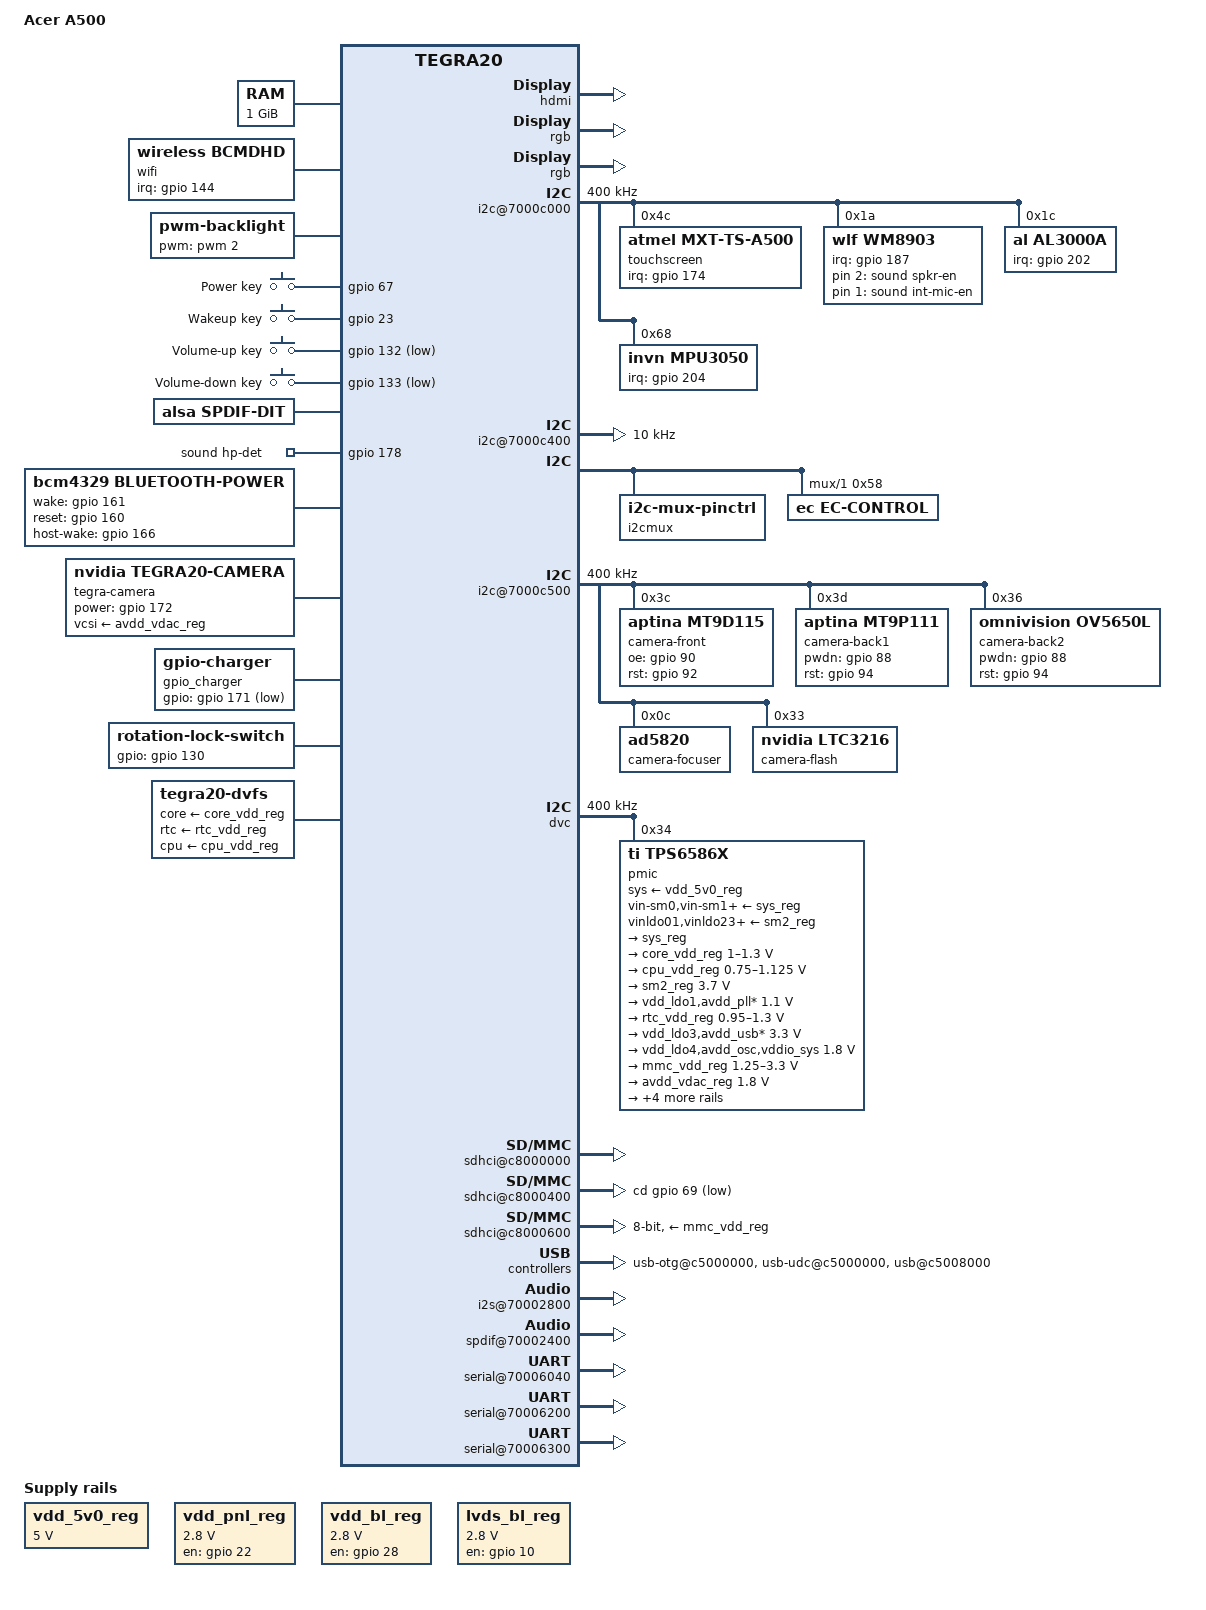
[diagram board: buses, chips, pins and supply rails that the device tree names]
/dts-v1/;

/*
 * Carveouts for multimedia and ram console
 * 256MB - multimedia
 * 9MB - fb1
 * 16MB - fb2
 * 1MB - console
 */
/memreserve/ 0x2E600000 0x11A00000;

/include/ "tegra20.dtsi"

/ {
	model = "Acer A500";
	compatible = "acer,picasso", "nvidia,tegra20";

	memory {
		reg = <0x00000000 0x40000000>;
	};

	nvmap {
		compatible = "nvidia,tegra-nvmap";
		#address-cells = <1>;
		#size-cells = <1>;
		ranges;

		carveouts {
			#address-cells = <1>;
			#size-cells = <1>;
			ranges;

			iram {
				reg = <0x40000400 0x3FC00>;
				reg-names = "iram";
				buddy-size = <0>;
				usage-mask = <0x20000000>;
			};

			generic {
				reg = <0x2E600000 0x10000000>;
				reg-names = "generic-0";
				buddy-size = <0x8000>;
				usage-mask = <0x1>;
			};
		};
	};

	host1x {
		compatible = "nvidia,tegra20-host1x", "nvhost-bus";
		ranges;

		hdmi {
			status = "okay";

			vdd-supply = <&hdmi_vdd_reg>;
			pll-supply = <&hdmi_pll_reg>;

			nvidia,ddc-i2c-bus = <&hdmi_ddc>;
			nvidia,hpd-gpio = <&gpio 111 0>; /* PN7 */
		};

		dc@54200000 {
			reg = <0x54200000 0x00040000>,
			      <0x3E600000 0x00900000>;
			reg-names = "regs", "fbmem";
			interrupt-names = "irq";

			lvds-vdd-supply = <&lvds_bl_reg>;
			pnl-vdd-supply = <&vdd_pnl_reg>;
			bl-vdd-supply = <&vdd_bl_reg>;

			rgb {
				status = "okay";

				display {
					fb-win = <0>;
					fb-xres = <1280>;
					fb-yres = <800>;
					fb-bpp = <32>;

					lvds-to-bl = <330>;

					dc-index = <0>;

					flags = <1>; /* TEGRA_DC_FLAG_ENABLED */

					type = <0>; /* TEGRA_DC_OUT_RGB */
					order = <0>; /* TEGRA_DC_ORDER_RED_BLUE */
					align = <0>; /* TEGRA_DC_ALIGN_MSB */
					depth = <18>;
					dither = <2>; /* TEGRA_DC_ORDERED_DITHER */

					default-emc-rate = <600000000>;
					min-emc-rate = <300000000>;

					display-timings {
						native-mode = <&timing0>;
						timing0: 1280x800 {
							clock-frequency = <70500000>;
							hactive = <1280>;
							vactive = <800>;
							hfront-porch = <58>;
							hback-porch = <4>;
							hsync-len = <58>;
							vsync-len = <4>;
							vfront-porch = <58>;
							vback-porch = <4>;
						};
					};
				};
			};
		};

		dc@54240000 {
			reg = <0x54240000 0x00040000>,
			      <0x54280000 0x00040000>,
			      <0x3EF00000 0x01000000>;
			reg-names = "regs", "hdmi_regs", "fbmem";
			interrupt-names = "irq";

			hdmi-vdd-supply = <&hdmi_vdd_reg>;
			hdmi-pll-supply = <&hdmi_pll_reg>;

			rgb {
				status = "okay";

				display {
					fb-win = <0>;
					fb-xres = <1280>;
					fb-yres = <800>;
					fb-bpp = <32>;

					dc-index = <1>;

					type = <1>; /* TEGRA_DC_OUT_HDMI */
					order = <0>; /* TEGRA_DC_ORDER_RED_BLUE */
					align = <0>; /* TEGRA_DC_ALIGN_MSB */
					dc-flags = <0>; /* TEGRA_DC_OUT_HOTPLUG_HIGH */
					max-clock = <148500>;
				};
			};
		};
	};

	pinmux {
		pinctrl-names = "default";
		pinctrl-0 = <&state_default>;

		state_default: pinmux {
			ata {
				nvidia,pins = "ata";
				nvidia,function = "ide";
			};
			atb {
				nvidia,pins = "atb", "gma", "gme";
				nvidia,function = "sdio4";
			};
			atc {
				nvidia,pins = "atc";
				nvidia,function = "nand";
			};
			atd {
				nvidia,pins = "atd", "ate", "gmb", "spia",
					"spib", "spic";
				nvidia,function = "gmi";
			};
			cdev1 {
				nvidia,pins = "cdev1";
				nvidia,function = "plla_out";
			};
			cdev2 {
				nvidia,pins = "cdev2";
				nvidia,function = "pllp_out4";
			};
			crtp {
				nvidia,pins = "crtp", "lm1";
				nvidia,function = "crt";
			};
			csus {
				nvidia,pins = "csus";
				nvidia,function = "vi_sensor_clk";
			};
			dap1 {
				nvidia,pins = "dap1";
				nvidia,function = "dap1";
			};
			dap2 {
				nvidia,pins = "dap2";
				nvidia,function = "dap2";
			};
			dap3 {
				nvidia,pins = "dap3";
				nvidia,function = "dap3";
			};
			dap4 {
				nvidia,pins = "dap4";
				nvidia,function = "dap4";
			};
			dta {
				nvidia,pins = "dta", "dtb", "dtc", "dtd", "dte";
				nvidia,function = "vi";
			};
			dtf {
				nvidia,pins = "dtf";
				nvidia,function = "i2c3";
			};
			gmc {
				nvidia,pins = "gmc";
				nvidia,function = "uartd";
			};
			gmd {
				nvidia,pins = "gmd";
				nvidia,function = "sflash";
			};
			gpu {
				nvidia,pins = "gpu";
				nvidia,function = "pwm";
			};
			gpu7 {
				nvidia,pins = "gpu7";
				nvidia,function = "rtck";
			};
			gpv {
				nvidia,pins = "gpv", "slxa";
				nvidia,function = "pcie";
			};
			hdint {
				nvidia,pins = "hdint";
				nvidia,function = "hdmi";
			};
			i2cp {
				nvidia,pins = "i2cp";
				nvidia,function = "i2cp";
			};
			irrx {
				nvidia,pins = "irrx", "irtx";
				nvidia,function = "uartb";
			};
			kbca {
				nvidia,pins = "kbca", "kbcb", "kbcc", "kbcd",
					"kbce", "kbcf";
				nvidia,function = "kbc";
			};
			lcsn {
				nvidia,pins = "lcsn", "ldc", "lm0", "lpw1",
					"lsdi", "lvp0";
				nvidia,function = "rsvd4";
			};
			ld0 {
				nvidia,pins = "ld0", "ld1", "ld2", "ld3", "ld4",
					"ld5", "ld6", "ld7", "ld8", "ld9",
					"ld10", "ld11", "ld12", "ld13", "ld14",
					"ld15", "ld16", "ld17", "ldi", "lhp0",
					"lhp1", "lhp2", "lhs", "lpp", "lsc0",
					"lsc1", "lsck", "lsda", "lspi", "lvp1",
					"lvs";
				nvidia,function = "displaya";
			};
			owc {
				nvidia,pins = "owc", "spdi", "spdo", "uac";
				nvidia,function = "rsvd2";
			};
			pmc {
				nvidia,pins = "pmc";
				nvidia,function = "pwr_on";
			};
			rm {
				nvidia,pins = "rm";
				nvidia,function = "i2c1";
			};
			sdb {
				nvidia,pins = "sdb", "sdc", "sdd", "slxc", "slxk";
				nvidia,function = "sdio3";
			};
			sdio1 {
				nvidia,pins = "sdio1";
				nvidia,function = "sdio1";
			};
			slxd {
				nvidia,pins = "slxd";
				nvidia,function = "spdif";
			};
			spid {
				nvidia,pins = "spid", "spie", "spif";
				nvidia,function = "spi1";
			};
			spig {
				nvidia,pins = "spig", "spih";
				nvidia,function = "spi2_alt";
			};
			uaa {
				nvidia,pins = "uaa", "uab", "uda";
				nvidia,function = "ulpi";
			};
			uad {
				nvidia,pins = "uad";
				nvidia,function = "irda";
			};
			uca {
				nvidia,pins = "uca", "ucb";
				nvidia,function = "uartc";
			};
			conf_ata {
				nvidia,pins = "ata", "atb", "atc", "atd",
					"cdev1", "cdev2", "csus", "dap1",
					"dap4", "dte", "dtf", "gma", "gmc",
					"gme", "gpu", "gpu7", "gpv", "i2cp",
					"irrx", "irtx", "pta", "rm",
					"sdc", "sdd", "slxc", "slxd", "slxk",
					"spdi", "spdo", "uac", "uad", "uda";
				nvidia,pull = <0>;
				nvidia,tristate = <0>;
			};
			conf_ate {
				nvidia,pins = "ate", "dap2", "dap3",
					"gmd", "owc", "spia", "spib", "spic",
					"spid", "spie";
				nvidia,pull = <0>;
				nvidia,tristate = <1>;
			};
			conf_ck32 {
				nvidia,pins = "ck32", "ddrc", "pmca", "pmcb",
					"pmcc", "pmcd", "pmce", "xm2c", "xm2d";
				nvidia,pull = <0>;
			};
			conf_crtp {
				nvidia,pins = "crtp", "gmb", "slxa", "spig",
					"spih";
				nvidia,pull = <2>;
				nvidia,tristate = <1>;
			};
			conf_dta {
				nvidia,pins = "dta", "dtb", "dtc", "dtd", "kbcb";
				nvidia,pull = <1>;
				nvidia,tristate = <0>;
			};
			conf_dte {
				nvidia,pins = "spif";
				nvidia,pull = <1>;
				nvidia,tristate = <1>;
			};
			conf_hdint {
				nvidia,pins = "hdint", "lcsn", "ldc", "lm1",
					"lpw1", "lsck", "lsda", "lsdi",
					"lvp0";
				nvidia,tristate = <1>;
			};
			conf_kbca {
				nvidia,pins = "kbca", "kbcc", "kbcd",
					"kbce", "kbcf", "sdio1", "uaa",
					"uab", "uca", "ucb";
				nvidia,pull = <2>;
				nvidia,tristate = <0>;
			};
			conf_lc {
				nvidia,pins = "lc", "ls";
				nvidia,pull = <2>;
			};
			conf_ld0 {
				nvidia,pins = "ld0", "ld1", "ld2", "ld3", "ld4",
					"ld5", "ld6", "ld7", "ld8", "ld9",
					"ld10", "ld11", "ld12", "ld13", "ld14",
					"ld15", "ld16", "ld17", "ldi", "lhp0",
					"lhp1", "lhp2", "lhs", "lm0", "lpp",
					"lpw0", "lpw2", "lsc0", "lsc1", "lspi",
					"lvp1", "lvs", "pmc", "sdb";
				nvidia,tristate = <0>;
			};
			conf_ld17_0 {
				nvidia,pins = "ld17_0", "ld19_18", "ld21_20",
					"ld23_22";
				nvidia,pull = <1>;
			};
			drive_ddc {
				nvidia,pins = "drive_ddc";
				nvidia,schmitt = <1>;
				nvidia,low-power-mode = <1>;
			};
			drive_vi1 {
				nvidia,pins = "drive_vi1";
				nvidia,schmitt = <1>;
				nvidia,low-power-mode = <1>;
			};
			drive_sdio1 {
				nvidia,pins = "drive_sdio1";
				nvidia,schmitt = <1>;
				nvidia,low-power-mode = <1>;
			};
			drive_dbg {
				nvidia,pins = "drive_dbg";
				nvidia,schmitt = <1>;
				nvidia,low-power-mode = <1>;
				nvidia,slew-rate-rising = <0>;
				nvidia,slew-rate-falling = <0>;
			};
			drive_vi2 {
				nvidia,pins = "drive_vi2";
				nvidia,schmitt = <1>;
				nvidia,low-power-mode = <1>;
				nvidia,slew-rate-rising = <0>;
				nvidia,slew-rate-falling = <0>;
			};
			drive_at1 {
				nvidia,pins = "drive_at1";
				nvidia,schmitt = <1>;
				nvidia,low-power-mode = <1>;
				nvidia,slew-rate-rising = <0>;
				nvidia,slew-rate-falling = <0>;
			};
			drive_ao1 {
				nvidia,pins = "drive_ao1";
				nvidia,schmitt = <1>;
				nvidia,low-power-mode = <1>;
				nvidia,slew-rate-rising = <0>;
				nvidia,slew-rate-falling = <0>;
			};
		};

		state_i2cmux_ddc: pinmux_i2cmux_ddc {
			ddc {
				nvidia,pins = "ddc";
				nvidia,function = "i2c2";
			};
			pta {
				nvidia,pins = "pta";
				nvidia,function = "rsvd4";
			};
		};

		state_i2cmux_pta: pinmux_i2cmux_pta {
			ddc {
				nvidia,pins = "ddc";
				nvidia,function = "rsvd4";
			};
			pta {
				nvidia,pins = "pta";
				nvidia,function = "i2c2";
			};
		};

		state_i2cmux_idle: pinmux_i2cmux_idle {
			ddc {
				nvidia,pins = "ddc";
				nvidia,function = "rsvd4";
			};
			pta {
				nvidia,pins = "pta";
				nvidia,function = "rsvd4";
			};
		};
	};

	i2c@7000c000 {
		status = "okay";
		clock-frequency = <400000>;

		touchscreen@4c {
			compatible = "atmel,mxt-ts-a500";
			reg = <0x4c>;
			interrupt-parent = <&gpio>;
			interrupts = <174 0x2>;

			android-evdev;
			multislot-proto;

			x-size = <1280>;
			y-size = <800>;

			config = /bits/ 8 <
				/* MXT_GEN_COMMAND(6) */
				0x00 0x00 0x00 0x00 0x00 0x00
				/* MXT_GEN_POWER(7) */
				0x32 0x0a 0x32
				/* MXT_GEN_ACQUIRE(8) */
				0x0a 0x00 0x0a 0x0a 0x00 0x00 0x05
				0x0a 0x1e 0x19
				/* MXT_TOUCH_MULTI(9) */
				0x8f 0x00 0x00 0x1c 0x29 0x00 0x10
				0x37 0x03 0x01 0x00 0x05 0x05 0x20
				0x0a 0x05 0x0a 0x05 0x1f 0x03 0xff
				0x04 0x00 0x00 0x00 0x00 0x98 0x22
				0xd4 0x16 0x0a 0x0a 0x00 0x00
				/* MXT_TOUCH_KEYARRAY(15-1) */
				0x01 0x18 0x29 0x04 0x01 0x00 0x00
				0xff 0x01 0x00 0x00
				/* MXT_TOUCH_KEYARRAY(15-2) */
				0x00 0x00 0x00 0x00 0x00 0x00 0x00
				0x00 0x00 0x00 0x00
				/* MXT_SPT_COMMSCONFIG(18) */
				0x00 0x00
				/* MXT_PROCG_NOISE(22) */
				0x05 0x00 0x00 0x00 0x00 0x00 0x00
				0x00 0x2D 0x00 0x00 0x0b 0x11 0x16
				0x20 0x24 0x00
				/* MXT_PROCI_ONETOUCH(24) */
				0x00 0x00 0x00 0x00 0x00 0x00 0x00
				0x00 0x00 0x00 0x00 0x00 0x00 0x00
				0x00 0x00 0x00 0x00 0x00
				/* MXT_SPT_SELFTEST(25) */
				0x00 0x00 0x00 0x00 0x00 0x00 0x00
				0x00 0x00 0x00 0x00 0x00 0x00 0x00
				/* MXT_PROCI_TWOTOUCH(27) */
				0x00 0x00 0x00 0x00 0x00 0x00 0x00
				/* MXT_SPT_CTECONFIG(28) */
				0x00 0x00 0x00 0x10 0x10 0x3c
				/* MXT_PROCI_GRIP(40) */
				0x00 0x00 0x00 0x00 0x00
				/* MXT_PROCI_PALM(41) */
				0x00 0x00 0x00 0x00 0x00 0x00
				/* MXT_TOUCH_PROXIMITY(43) */
				0x00 0x00 0x00 0x00 0x00 0x00>;
		};

		wm8903: wm8903@1a {
			compatible = "wlf,wm8903";
			reg = <0x1a>;
			interrupt-parent = <&gpio>;
			interrupts = <187 0x04>;

			gpio-controller;
			#gpio-cells = <2>;

			micdet-cfg = <0>;
			micdet-delay = <500>;
			gpio-cfg = <0 0 0 0xffffffff 0xffffffff>;
		};

		al3000a@1c {
			compatible = "al,al3000a";
			reg = <0x1c>;
			interrupt-parent = <&gpio>;
			interrupts = <202 0x04>; /* GPIO PZ2 */
		};

		mpu3050@68 {
			compatible = "invn,mpu3050";
			reg = <0x68>;
			interrupt-parent = <&gpio>;
			interrupts = <204 0x04>; /* gpio PZ4 */

			compass-i2c-bus = <&dvc>;
			compass-yamaha-i2c-bus = <&dvc>;

			int-config = <0x10>;
			level-shifter = <0>;
			orientation = /bits/ 8 <0	0xff	0
						0xff	0	0
						0	0	0xff>;

			accelerometer {
				interrupt-parent = <&gpio>;
				interrupts = <151 0x04>; /* gpio PS7 */

				bus-secondary;
				address = <0xf>;
				orientation = /bits/ 8 <0	0xff	0
							0xff	0	0
							0	0	0xff>;
			};

			compass {
				interrupt-parent = <&gpio>;
				interrupts = <109 0x04>; /* gpio PN5 */

				bus-primary;
				address = <0xc>;
				orientation = /bits/ 8 <1	0	0
							0	0xff	0
							0	0	0xff>;
			};
		};
	};

	i2c@7000c400 {
		status = "okay";
		clock-frequency = <10000>;
	};

	i2cmux {
		compatible = "i2c-mux-pinctrl";
		#address-cells = <1>;
		#size-cells = <0>;

		i2c-parent = <&{/i2c@7000c400}>;

		pinctrl-names = "ddc", "pta", "idle";
		pinctrl-0 = <&state_i2cmux_ddc>;
		pinctrl-1 = <&state_i2cmux_pta>;
		pinctrl-2 = <&state_i2cmux_idle>;

		hdmi_ddc: i2c@0 {
			reg = <0>;
			#address-cells = <1>;
			#size-cells = <0>;
		};

		i2c@1 {
			reg = <1>;
			#address-cells = <1>;
			#size-cells = <0>;

			ec-control@58 {
				compatible = "ec,ec-control";
				reg = <0x58>;
				ec,i2c-retry-count = <5>;
				ec,lsc-start-delay = <25000>;
				system-power-controller;
				leds-reset;

				battery {
					compatible = "ec,ec-battery";
					power-supply = <&gpio_charger>;
				};

				leds {
					compatible = "ec,ec-leds";
				};
			};
		};
	};

	i2c@7000c500 {
		status = "okay";
		clock-frequency = <400000>;

		camera-front@3c {
			compatible = "aptina,mt9d115";
			reg = <0x3c>;
			oe-gpio = <&gpio 90 0>; /* gpio PL2 */
			rst-gpio = <&gpio 92 0>; /* gpio PL4 */
		};

		camera-back1@3d {
			compatible = "aptina,mt9p111";
			reg = <0x3d>;
			pwdn-gpio = <&gpio 88 0>; /* gpio PL0 */
			rst-gpio = <&gpio 94 0>; /* gpio PL6 */
		};

		camera-back2@36 {
			compatible = "omnivision,ov5650l";
			reg = <0x36>;
			pwdn-gpio = <&gpio 88 0>; /* gpio PL0 */
			rst-gpio = <&gpio 94 0>; /* gpio PL6 */
		};

		camera-focuser@0c {
			compatible = "ad5820";
			reg = <0x0c>;
		};

		camera-flash@33 {
			compatible = "nvidia,ltc3216";
			reg = <0x33>;
		};
	};

	regulators {
		compatible = "simple-bus";
		#address-cells = <1>;
		#size-cells = <0>;

		vdd_5v0_reg: regulator@0 {
			compatible = "regulator-fixed";
			reg = <0>;
			regulator-name = "vdd_5v0";
			regulator-min-microvolt = <5000000>;
			regulator-max-microvolt = <5000000>;
			regulator-always-on;
		};

		vdd_pnl_reg: regulator@1 {
			compatible = "regulator-fixed";
			reg = <1>;
			regulator-name = "vdd_pnl";
			regulator-min-microvolt = <2800000>;
			regulator-max-microvolt = <2800000>;
			gpio = <&gpio 22 0>; /* gpio PC6 */
			enable-active-high;
			regulator-boot-on;
		};

		vdd_bl_reg: regulator@2 {
			compatible = "regulator-fixed";
			reg = <2>;
			regulator-name = "vdd_bl";
			regulator-min-microvolt = <2800000>;
			regulator-max-microvolt = <2800000>;
			gpio = <&gpio 28 0>; /* gpio PD4 */
			enable-active-high;
			regulator-boot-on;
		};

		lvds_bl_reg: regulator@3 {
			compatible = "regulator-fixed";
			reg = <3>;
			regulator-name = "vdd_lvds";
			regulator-min-microvolt = <2800000>;
			regulator-max-microvolt = <2800000>;
			gpio = <&gpio 10 0>; /* gpio PB2 */
			enable-active-high;
			regulator-boot-on;
		};
	};

	dvc: i2c@7000d000 {
		status = "okay";
		clock-frequency = <400000>;

		pmic: tps6586x@34 {
			compatible = "ti,tps6586x";
			reg = <0x34>;
			interrupts = <0 86 0>;

			#gpio-cells = <2>;
			gpio-controller;

			sys-supply = <&vdd_5v0_reg>;
			vin-sm0-supply = <&sys_reg>;
			vin-sm1-supply = <&sys_reg>;
			vin-sm2-supply = <&sys_reg>;
			vinldo01-supply = <&sm2_reg>;
			vinldo23-supply = <&sm2_reg>;
			vinldo4-supply = <&sm2_reg>;
			vinldo678-supply = <&sm2_reg>;
			vinldo9-supply = <&sm2_reg>;

			regulators {
				sys_reg: sys {
					regulator-name = "vdd_sys";
					regulator-always-on;
				};

				core_vdd_reg: sm0 {
					regulator-name = "vdd_sm0,vdd_core";
					regulator-min-microvolt = <1000000>;
					regulator-max-microvolt = <1300000>;
					regulator-always-on;
				};

				cpu_vdd_reg: sm1 {
					regulator-name = "vdd_sm1,vdd_cpu";
					regulator-min-microvolt = <750000>;
					regulator-max-microvolt = <1125000>;
					regulator-always-on;
				};

				sm2_reg: sm2 {
					regulator-name = "vdd_sm2,vin_ldo*";
					regulator-min-microvolt = <3700000>;
					regulator-max-microvolt = <3700000>;
					regulator-always-on;
				};

				/* LDO0 is not connected to anything */

				ldo1 {
					regulator-name = "vdd_ldo1,avdd_pll*";
					regulator-min-microvolt = <1100000>;
					regulator-max-microvolt = <1100000>;
					regulator-always-on;
				};

				rtc_vdd_reg: ldo2 {
					regulator-name = "vdd_ldo2,vdd_rtc";
					regulator-min-microvolt = <950000>;
					regulator-max-microvolt = <1300000>;
				};

				ldo3 {
					regulator-name = "vdd_ldo3,avdd_usb*";
					regulator-min-microvolt = <3300000>;
					regulator-max-microvolt = <3300000>;
					regulator-always-on;
				};

				ldo4 {
					regulator-name = "vdd_ldo4,avdd_osc,vddio_sys";
					regulator-min-microvolt = <1800000>;
					regulator-max-microvolt = <1800000>;
					regulator-always-on;
				};

				mmc_vdd_reg: ldo5 {
					regulator-name = "vdd_ldo5,vcore_mmc";
					regulator-min-microvolt = <1250000>;
					regulator-max-microvolt = <3300000>;
					regulator-always-on;
				};

				avdd_vdac_reg: ldo6 {
					regulator-name = "vdd_ldo6,avdd_vdac";
					regulator-min-microvolt = <1800000>;
					regulator-max-microvolt = <1800000>;
				};

				hdmi_vdd_reg: ldo7 {
					regulator-name = "vdd_ldo7,avdd_hdmi";
					regulator-min-microvolt = <3300000>;
					regulator-max-microvolt = <3300000>;
				};

				hdmi_pll_reg: ldo8 {
					regulator-name = "vdd_ldo8,avdd_hdmi_pll";
					regulator-min-microvolt = <1800000>;
					regulator-max-microvolt = <1800000>;
				};

				ldo9 {
					regulator-name = "vdd_ldo9,avdd_2v85,vdd_ddr_rx";
					regulator-min-microvolt = <2850000>;
					regulator-max-microvolt = <2850000>;
				};

				ldo_rtc {
					regulator-name = "vdd_rtc_out,vdd_cell";
					regulator-min-microvolt = <3300000>;
					regulator-max-microvolt = <3300000>;
				};
			};
		};
	};

	pmc {
		nvidia,invert-interrupt;
	};

	sdhci@c8000000 {
		status = "okay";
	};

	sdhci@c8000400 {
		status = "okay";
		cd-gpios = <&gpio 69 1>; /* gpio PI5 */
		power-gpios = <&gpio 70 0>; /* gpio PI6 */
	};

	sdhci@c8000600 {
		status = "okay";
		built-in;
		bus-width = <8>;
		vmmc-supply = <&mmc_vdd_reg>;
	};

	wifi {
		compatible = "wireless,bcmdhd";
		interrupt-parent = <&gpio>;
		interrupts = <144 0x04>; /* gpio PS0 */
		interrupt-names = "bcmdhd_wlan_irq";
	};

	usb-otg@c5000000 {
		compatible = "nvidia,tegra20-otg";
		reg = <0xc5000000 0x4000>;
		interrupts = <0 20 0x04>;
		nvidia,vbus-gpio = <&gpio 24 0>; /* gpio PD0 */
	};

	usb-udc@c5000000 {
		compatible = "nvidia,tegra20-udc";
		reg = <0xc5000000 0x4000>;
		interrupts = <0 20 0x04>;
	};

	usb@c5008000 {
		status = "okay";
		nvidia,vbus-gpio = <&gpio 27 0>; /* gpio PD3 */
	};

	ram-console {
		compatible = "android,ram-console";
		reg = <0x3FF00000 0x00100000>;
	};

	backlight {
		compatible = "pwm-backlight";
		pwms = <&pwm 2 41667>;

		brightness-levels = <0 1 2 3 4 5 6 7 8 9 10 11 12 13 14 15 16 17
				18 19 20 21 22 23 24 25 26 27 28 29 30 31 32 33
				34 35 36 37 38 39 40 41 42 43 44 45 46 47 48 49
				50 51 52 53 54 55 56 57 58 59 60 61 62 63 64 65
				66 67 68 69 70 71 72 73 74 75 76 77 78 79 80 81
				82 83 84 85 86 87 88 89 90 91 92 93 94 95 96 97
				98 99 100 101 102 103 104 105 106 107 108 109
				110 111 112 113 114 115 116 117 118 119 120 121
				122 123 124 125 126 127 128 129 130 131 132 133
				134 135 136 137 138 139 140 141 142 143 144 145
				146 147 148 149 150 151 152 153 154 155 156 157
				158 159 160 161 162 163 164 165 166 167 168 169
				170 171 172 173 174 175 176 177 178 179 180 181
				182 183 184 185 186 187 188 189 190 191 192 193
				194 195 196 197 198 199 200 201 202 203 204 205
				206 207 208 209 210 211 212 213 214 215 216 217
				218 219 220 221 222 223 224 225 226 227 228 229
				230 231 232 233 234 235 236 237 238 239 240 241
				242 243 244 245 246 247 248 249 250 251 252 253
				254 255>;

		default-brightness-level = <224>;
	};

	gpio-keys {
		compatible = "gpio-keys";

		power {
			label = "Power key";
			gpios = <&gpio 67 0>; /* gpio PI3 */
			linux,code = <116>; /* KEY_POWER */
			debounce-interval = <0>;
		};

		wakeup {
			label = "Wakeup key";
			gpios = <&gpio 23 0>; /* gpio PC7 */
			linux,code = <116>; /* KEY_POWER */
			gpio-key,wakeup;
			debounce-interval = <0>;
		};

		volume-up {
			label = "Volume-up key";
			gpios = <&gpio 132 1>; /* gpio PQ4 */
			linux,code = <115>; /* KEY_VOLUMEUP */
			debounce-interval = <10>;
		};

		volume-down {
			label = "Volume-down key";
			gpios = <&gpio 133 1>; /* gpio PQ5 */
			linux,code = <114>; /* KEY_VOLUMEDOWN */
			debounce-interval = <10>;
		};
	};

	i2s@70002800 {
		status = "okay";
	};

	spdif-dit {
		compatible = "alsa,spdif-dit";
	};

	spdif@70002400 {
		compatible = "nvidia,tegra20-spdif";
		reg = <0x70002400 0x00000200>,
		      <0x00000003 0x00000003>;
		reg-names = "regs", "dma";
	};

	sound {
		compatible = "nvidia,tegra-audio-wm8903-picasso",
			     "nvidia,tegra-audio-wm8903";
		nvidia,model = "WM8903 NVIDIA Tegra Picasso";

		nvidia,audio-routing =
			"Headphone Jack", "HPOUTR",
			"Headphone Jack", "HPOUTL",
			"Int Spk", "LINEOUTL",
			"Int Spk", "LINEOUTR",
			"Mic Jack", "MICBIAS",
			"IN2L", "Mic Jack",
			"IN2R", "Mic Jack",
			"Int Mic", "MICBIAS",
			"IN1L", "Int Mic",
			"IN1R", "Int Mic";

		nvidia,i2s-controller = <&tegra_i2s1>;
		nvidia,audio-codec = <&wm8903>;

		nvidia,spkr-en-gpios = <&wm8903 2 0>;
		nvidia,hp-det-gpios = <&gpio 178 0>; /* gpio PW2 */
		nvidia,int-mic-en-gpios = <&wm8903 1 0>; /* gpio FM2018 */

		vdd_dmic-supply = <&avdd_vdac_reg>;
	};

	serial@70006040 {
		status = "okay";
		compatible = "nvidia,tegra20-hsuart";
		nvidia,dma-request-selector = <&apbdma 9>;
	};

	serial@70006200 {
		status = "okay";
		compatible = "nvidia,tegra20-hsuart";
		nvidia,dma-request-selector = <&apbdma 10>;
	};

	serial@70006300 {
		status = "okay";
		compatible = "nvidia,tegra20-hsuart";
		nvidia,dma-request-selector = <&apbdma 19>;
	};

	bluetooth-power {
		compatible = "bcm4329,bluetooth-power";

		wake-gpio = <&gpio 161 0>; /* gpio PU1 */
		reset-gpio = <&gpio 160 0>; /* gpio PU0 */
		host-wake-gpio = <&gpio 166 0>; /* gpio PU6 */
	};

	tegra-avp {
		compatible = "nvidia,tegra20-avp";
		interrupts = <0 4 0x04>;
		interrupt-names = "mbox_from_avp_pending";
	};

	tegra-camera {
		compatible = "nvidia,tegra20-camera";
		power-gpio = <&gpio 172 0>; /* gpio PV4 */
		vcsi-supply = <&avdd_vdac_reg>;
	};

	tegra-aes@6001a000 {
		compatible = "nvidia,tegra20-aes";
		reg = <0x6001a000 0x3c00>;
		interrupts = <0 10 0x04>;
	};

	timed-gpio {
		compatible = "android,timed-gpio";

		vibrator {
			gpio = <&gpio 173 0>; /* gpio PV5 */
			name = "vibrator";
			max-timeout = <10000>;
		};
	};

	wakeups {
		compatible = "nvidia,tegra20-wakeups";

		gpio-events-1 {
			interrupt-parent = <&gpio>;
			interrupts = <117 0>, /* PO5 */
				     <171 0>, /* PV3 */
				     <89  0>, /* PL1 */
				     <14  0>, /* PB6 */
				     <111 0>, /* PN7 */
				     <0   0>, /* PA0 */
				     <165 0>, /* PU5 */
				     <166 0>, /* PU6 */
				     <23  0>, /* PC7 */
				     <146 0>, /* PS2 */
				     <209 0>, /* PAA1 */
				     <179 0>, /* PW3 */
				     <178 0>, /* PW2 */
				     <198 0>, /* PY6 */
				     <174 0>, /* PV6 */
				     <79  0>; /* PJ7 */
			count = <16>;
		};

		gic-events {
			interrupts = <0 2  0>, /* rtc */
				     <0 85 0>, /* kbc */
				     <0 86 0>, /* pmu */
				     <0 20 0>; /* usb1 vbus */
			count = <4>;
		};

		unused-events {
			interrupt-parent = <0>;
			interrupts = <0 97 0>, /* usb3 vbus */
				     <0 0 0>, /* usb1 id */
				     <0 0 0>; /* usb3 id */
			count = <3>;
		};

		gpio-events-2 {
			interrupt-parent = <&gpio>;
			interrupts = <69  0>, /* PI5 */
				     <170 0>, /* PV2 */
				     <148 0>, /* PS4 */
				     <149 0>, /* PS5 */
				     <144 0>, /* PS0 */
				     <134 0>, /* PQ6 */
				     <135 0>, /* PQ7 */
				     <106 0>; /* PN2 */
			count = <8>;
		};
	};

	gpio_charger: charger {
		compatible = "gpio-charger";
		charger-type = <3>;
		gpio = <&gpio 171 1>; /* gpio PV3 */
	};

	rotation-lock {
		compatible = "rotation-lock-switch";
		gpio = <&gpio 130 0>; /* gpio PQ2 */
	};

	dvfs {
		compatible = "tegra20-dvfs";
		core-supply = <&core_vdd_reg>;
		rtc-supply = <&rtc_vdd_reg>;
		cpu-supply = <&cpu_vdd_reg>;
	};

	memory-controller@7000f400 {
		nvidia,use-ram-code;

		elpida-8gb {
			nvidia,ram-code = <0x0>;
			#address-cells = <1>;
			#size-cells = <0>;

			emc-table@25000 {
				reg = <25000>;
				compatible = "nvidia,tegra20-emc-table";
				clock-frequency = <25000>;
				nvidia,emc-registers = <0x00000002 0x00000006
					0x00000003 0x00000003 0x00000006 0x00000004
					0x00000002 0x00000009 0x00000003 0x00000003
					0x00000002 0x00000002 0x00000002 0x00000004
					0x00000003 0x00000008 0x0000000b 0x0000004d
					0x00000000 0x00000003 0x00000003 0x00000003
					0x00000008 0x00000001 0x0000000a 0x00000004
					0x00000003 0x00000008 0x00000004 0x00000006
					0x00000002 0x00000068 0x00000000 0x00000003
					0x00000000 0x00000000 0x00000282 0xa0ae04ae
					0x00070000 0x00000000 0x00000000 0x00000003
					0x00000000 0x00000000 0x00000000 0x00000000>;
			};

			emc-table@50000 {
				reg = <50000>;
				compatible = "nvidia,tegra20-emc-table";
				clock-frequency = <50000>;
				nvidia,emc-registers = <0x00000003 0x00000007
					0x00000003 0x00000003 0x00000006 0x00000004
					0x00000002 0x00000009 0x00000003 0x00000003
					0x00000002 0x00000002 0x00000002 0x00000005
					0x00000003 0x00000008 0x0000000b 0x0000009f
					0x00000000 0x00000003 0x00000003 0x00000003
					0x00000008 0x00000001 0x0000000a 0x00000007
					0x00000003 0x00000008 0x00000004 0x00000006
					0x00000002 0x000000d0 0x00000000 0x00000000
					0x00000000 0x00000000 0x00000282 0xa0ae04ae
					0x00070000 0x00000000 0x00000000 0x00000005
					0x00000000 0x00000000 0x00000000 0x00000000>;
			};

			emc-table@75000 {
				reg = <75000>;
				compatible = "nvidia,tegra20-emc-table";
				clock-frequency = <75000>;
				nvidia,emc-registers = <0x00000005 0x0000000a
					0x00000004 0x00000003 0x00000006 0x00000004
					0x00000002 0x00000009 0x00000003 0x00000003
					0x00000002 0x00000002 0x00000002 0x00000005
					0x00000003 0x00000008 0x0000000b 0x000000ff
					0x00000000 0x00000003 0x00000003 0x00000003
					0x00000008 0x00000001 0x0000000a 0x0000000b
					0x00000003 0x00000008 0x00000004 0x00000006
					0x00000002 0x00000138 0x00000000 0x00000000
					0x00000000 0x00000000 0x00000282 0xa0ae04ae
					0x00070000 0x00000000 0x00000000 0x00000007
					0x00000000 0x00000000 0x00000000 0x00000000>;
			};

			emc-table@150000 {
				reg = <150000>;
				compatible = "nvidia,tegra20-emc-table";
				clock-frequency = <150000>;
				nvidia,emc-registers = <0x00000009 0x00000014
					0x00000007 0x00000003 0x00000006 0x00000004
					0x00000002 0x00000009 0x00000003 0x00000003
					0x00000002 0x00000002 0x00000002 0x00000005
					0x00000003 0x00000008 0x0000000b 0x0000021f
					0x00000000 0x00000003 0x00000003 0x00000003
					0x00000008 0x00000001 0x0000000a 0x00000015
					0x00000003 0x00000008 0x00000004 0x00000006
					0x00000002 0x00000270 0x00000000 0x00000001
					0x00000000 0x00000000 0x00000282 0xa07c04ae
					0x007dd510 0x00000000 0x00000000 0x0000000e
					0x00000000 0x00000000 0x00000000 0x00000000>;
			};

			emc-table@300000 {
				reg = <300000>;
				compatible = "nvidia,tegra20-emc-table";
				clock-frequency = <300000>;
				nvidia,emc-registers = <0x00000012 0x00000027
					0x0000000d 0x00000006 0x00000007 0x00000005
					0x00000003 0x00000009 0x00000006 0x00000006
					0x00000003 0x00000003 0x00000002 0x00000006
					0x00000003 0x00000009 0x0000000c 0x0000045f
					0x00000000 0x00000004 0x00000004 0x00000006
					0x00000008 0x00000001 0x0000000e 0x0000002a
					0x00000003 0x0000000f 0x00000007 0x00000005
					0x00000002 0x000004e1 0x00000005 0x00000002
					0x00000000 0x00000000 0x00000282 0xe059048b
					0x007e1510 0x00000000 0x00000000 0x0000001b
					0x00000000 0x00000000 0x00000000 0x00000000>;
			};
		};

		elpida-4gb {
			nvidia,ram-code = <0x1>;
			#address-cells = <1>;
			#size-cells = <0>;

			emc-table@25000 {
				reg = <25000>;
				compatible = "nvidia,tegra20-emc-table";
				clock-frequency = <25000>;
				nvidia,emc-registers = <0x00000002 0x00000006
					0x00000003 0x00000003 0x00000006 0x00000004
					0x00000002 0x00000009 0x00000003 0x00000003
					0x00000002 0x00000002 0x00000002 0x00000004
					0x00000003 0x00000008 0x0000000b 0x0000004d
					0x00000000 0x00000003 0x00000003 0x00000003
					0x00000008 0x00000001 0x0000000a 0x00000004
					0x00000003 0x00000008 0x00000004 0x00000006
					0x00000002 0x00000068 0x00000000 0x00000003
					0x00000000 0x00000000 0x00000282 0xa0ae04ae
					0x0007c000 0x00000000 0x00000000 0x00000003
					0x00000000 0x00000000 0x00000000 0x00000000>;
			};

			emc-table@50000 {
				reg = <50000>;
				compatible = "nvidia,tegra20-emc-table";
				clock-frequency = <50000>;
				nvidia,emc-registers = <0x00000003 0x00000007
					0x00000003 0x00000003 0x00000006 0x00000004
					0x00000002 0x00000009 0x00000003 0x00000003
					0x00000002 0x00000002 0x00000002 0x00000005
					0x00000003 0x00000008 0x0000000b 0x0000009f
					0x00000000 0x00000003 0x00000003 0x00000003
					0x00000008 0x00000001 0x0000000a 0x00000007
					0x00000003 0x00000008 0x00000004 0x00000006
					0x00000002 0x000000d0 0x00000000 0x00000000
					0x00000000 0x00000000 0x00000282 0xa0ae04ae
					0x0007c000 0x00000000 0x00000000 0x00000005
					0x00000000 0x00000000 0x00000000 0x00000000>;
			};

			emc-table@75000 {
				reg = <75000>;
				compatible = "nvidia,tegra20-emc-table";
				clock-frequency = <75000>;
				nvidia,emc-registers = <0x00000005 0x0000000a
					0x00000004 0x00000003 0x00000006 0x00000004
					0x00000002 0x00000009 0x00000003 0x00000003
					0x00000002 0x00000002 0x00000002 0x00000005
					0x00000003 0x00000008 0x0000000b 0x000000ff
					0x00000000 0x00000003 0x00000003 0x00000003
					0x00000008 0x00000001 0x0000000a 0x0000000b
					0x00000003 0x00000008 0x00000004 0x00000006
					0x00000002 0x00000138 0x00000000 0x00000000
					0x00000000 0x00000000 0x00000282 0xa0ae04ae
					0x0007c000 0x00000000 0x00000000 0x00000007
					0x00000000 0x00000000 0x00000000 0x00000000>;
			};

			emc-table@150000 {
				reg = <150000>;
				compatible = "nvidia,tegra20-emc-table";
				clock-frequency = <150000>;
				nvidia,emc-registers = <0x00000009 0x00000014
					0x00000007 0x00000003 0x00000006 0x00000004
					0x00000002 0x00000009 0x00000003 0x00000003
					0x00000002 0x00000002 0x00000002 0x00000005
					0x00000003 0x00000008 0x0000000b 0x0000021f
					0x00000000 0x00000003 0x00000003 0x00000003
					0x00000008 0x00000001 0x0000000a 0x00000015
					0x00000003 0x00000008 0x00000004 0x00000006
					0x00000002 0x00000270 0x00000000 0x00000001
					0x00000000 0x00000000 0x00000282 0xa07c04ae
					0x007e4010 0x00000000 0x00000000 0x0000000e
					0x00000000 0x00000000 0x00000000 0x00000000>;
			};

			emc-table@300000 {
				reg = <300000>;
				compatible = "nvidia,tegra20-emc-table";
				clock-frequency = <300000>;
				nvidia,emc-registers = <0x00000012 0x00000027
					0x0000000d 0x00000006 0x00000007 0x00000005
					0x00000003 0x00000009 0x00000006 0x00000006
					0x00000003 0x00000003 0x00000002 0x00000006
					0x00000003 0x00000009 0x0000000c 0x0000045f
					0x00000000 0x00000004 0x00000004 0x00000006
					0x00000008 0x00000001 0x0000000e 0x0000002a
					0x00000003 0x0000000f 0x00000007 0x00000005
					0x00000002 0x000004e1 0x00000005 0x00000002
					0x00000000 0x00000000 0x00000282 0xe059048b
					0x007e0010 0x00000000 0x00000000 0x0000001b
					0x00000000 0x00000000 0x00000000 0x00000000>;
			};
		};

		hynix-8gb {
			nvidia,ram-code = <0x2>;
			#address-cells = <1>;
			#size-cells = <0>;

			emc-table@25000 {
				reg = <25000>;
				compatible = "nvidia,tegra20-emc-table";
				clock-frequency = <25000>;
				nvidia,emc-registers = <0x00000002 0x00000006
					0x00000003 0x00000003 0x00000006 0x00000004
					0x00000002 0x00000009 0x00000003 0x00000003
					0x00000002 0x00000002 0x00000002 0x00000004
					0x00000003 0x00000008 0x0000000b 0x0000004d
					0x00000000 0x00000003 0x00000003 0x00000003
					0x00000008 0x00000001 0x0000000a 0x00000004
					0x00000003 0x00000008 0x00000004 0x00000006
					0x00000002 0x00000068 0x00000000 0x00000003
					0x00000000 0x00000000 0x00000282 0xa0ae04ae
					0x00070000 0x00000000 0x00000000 0x00000003
					0x00000000 0x00000000 0x00000000 0x00000000>;
			};

			emc-table@50000 {
				reg = <50000>;
				compatible = "nvidia,tegra20-emc-table";
				clock-frequency = <50000>;
				nvidia,emc-registers = <0x00000003 0x00000007
					0x00000003 0x00000003 0x00000006 0x00000004
					0x00000002 0x00000009 0x00000003 0x00000003
					0x00000002 0x00000002 0x00000002 0x00000005
					0x00000003 0x00000008 0x0000000b 0x0000009f
					0x00000000 0x00000003 0x00000003 0x00000003
					0x00000008 0x00000001 0x0000000a 0x00000007
					0x00000003 0x00000008 0x00000004 0x00000006
					0x00000002 0x000000d0 0x00000000 0x00000000
					0x00000000 0x00000000 0x00000282 0xa0ae04ae
					0x00070000 0x00000000 0x00000000 0x00000005
					0x00000000 0x00000000 0x00000000 0x00000000>;
			};

			emc-table@75000 {
				reg = <75000>;
				compatible = "nvidia,tegra20-emc-table";
				clock-frequency = <75000>;
				nvidia,emc-registers = <0x00000005 0x0000000a
					0x00000004 0x00000003 0x00000006 0x00000004
					0x00000002 0x00000009 0x00000003 0x00000003
					0x00000002 0x00000002 0x00000002 0x00000005
					0x00000003 0x00000008 0x0000000b 0x000000ff
					0x00000000 0x00000003 0x00000003 0x00000003
					0x00000008 0x00000001 0x0000000a 0x0000000b
					0x00000003 0x00000008 0x00000004 0x00000006
					0x00000002 0x00000138 0x00000000 0x00000000
					0x00000000 0x00000000 0x00000282 0xa0ae04ae
					0x00070000 0x00000000 0x00000000 0x00000007
					0x00000000 0x00000000 0x00000000 0x00000000>;
			};

			emc-table@150000 {
				reg = <150000>;
				compatible = "nvidia,tegra20-emc-table";
				clock-frequency = <150000>;
				nvidia,emc-registers = <0x00000009 0x00000014
					0x00000007 0x00000003 0x00000006 0x00000004
					0x00000002 0x00000009 0x00000003 0x00000003
					0x00000002 0x00000002 0x00000002 0x00000005
					0x00000003 0x00000008 0x0000000b 0x0000021f
					0x00000000 0x00000003 0x00000003 0x00000003
					0x00000008 0x00000001 0x0000000a 0x00000015
					0x00000003 0x00000008 0x00000004 0x00000006
					0x00000002 0x00000270 0x00000000 0x00000001
					0x00000000 0x00000000 0x00000282 0xa07c04ae
					0x007dd010 0x00000000 0x00000000 0x0000000e
					0x00000000 0x00000000 0x00000000 0x00000000>;
			};

			emc-table@300000 {
				reg = <300000>;
				compatible = "nvidia,tegra20-emc-table";
				clock-frequency = <300000>;
				nvidia,emc-registers = <0x00000012 0x00000027
					0x0000000d 0x00000006 0x00000007 0x00000005
					0x00000003 0x00000009 0x00000006 0x00000006
					0x00000003 0x00000003 0x00000002 0x00000006
					0x00000003 0x00000009 0x0000000c 0x0000045f
					0x00000000 0x00000004 0x00000004 0x00000006
					0x00000008 0x00000001 0x0000000e 0x0000002a
					0x00000003 0x0000000f 0x00000007 0x00000005
					0x00000002 0x000004e1 0x00000005 0x00000002
					0x00000000 0x00000000 0x00000282 0xe059048b
					0x007e2010 0x00000000 0x00000000 0x0000001b
					0x00000000 0x00000000 0x00000000 0x00000000>;
			};
		};

		hynix-4gb {
			nvidia,ram-code = <0x3>;
			#address-cells = <1>;
			#size-cells = <0>;

			emc-table@25000 {
				reg = <25000>;
				compatible = "nvidia,tegra20-emc-table";
				clock-frequency = <25000>;
				nvidia,emc-registers = <0x00000002 0x00000006
					0x00000003 0x00000003 0x00000006 0x00000004
					0x00000002 0x00000009 0x00000003 0x00000003
					0x00000002 0x00000002 0x00000002 0x00000004
					0x00000003 0x00000008 0x0000000b 0x0000004d
					0x00000000 0x00000003 0x00000003 0x00000003
					0x00000008 0x00000001 0x0000000a 0x00000004
					0x00000003 0x00000008 0x00000004 0x00000006
					0x00000002 0x00000068 0x00000000 0x00000003
					0x00000000 0x00000000 0x00000282 0xa0ae04ae
					0x0007c000 0x00000000 0x00000000 0x00000003
					0x00000000 0x00000000 0x00000000 0x00000000>;
			};

			emc-table@50000 {
				reg = <50000>;
				compatible = "nvidia,tegra20-emc-table";
				clock-frequency = <50000>;
				nvidia,emc-registers = <0x00000003 0x00000007
					0x00000003 0x00000003 0x00000006 0x00000004
					0x00000002 0x00000009 0x00000003 0x00000003
					0x00000002 0x00000002 0x00000002 0x00000005
					0x00000003 0x00000008 0x0000000b 0x0000009f
					0x00000000 0x00000003 0x00000003 0x00000003
					0x00000008 0x00000001 0x0000000a 0x00000007
					0x00000003 0x00000008 0x00000004 0x00000006
					0x00000002 0x000000d0 0x00000000 0x00000000
					0x00000000 0x00000000 0x00000282 0xa0ae04ae
					0x0007c000 0x00078000 0x00000000 0x00000005
					0x00000000 0x00000000 0x00000000 0x00000000>;
			};

			emc-table@75000 {
				reg = <75000>;
				compatible = "nvidia,tegra20-emc-table";
				clock-frequency = <75000>;
				nvidia,emc-registers = <0x00000005 0x0000000a
					0x00000004 0x00000003 0x00000006 0x00000004
					0x00000002 0x00000009 0x00000003 0x00000003
					0x00000002 0x00000002 0x00000002 0x00000005
					0x00000003 0x00000008 0x0000000b 0x000000ff
					0x00000000 0x00000003 0x00000003 0x00000003
					0x00000008 0x00000001 0x0000000a 0x0000000b
					0x00000003 0x00000008 0x00000004 0x00000006
					0x00000002 0x00000138 0x00000000 0x00000000
					0x00000000 0x00000000 0x00000282 0xa0ae04ae
					0x0007c000 0x00000000 0x00000000 0x00000007
					0x00000000 0x00000000 0x00000000 0x00000000>;
			};

			emc-table@150000 {
				reg = <150000>;
				compatible = "nvidia,tegra20-emc-table";
				clock-frequency = <150000>;
				nvidia,emc-registers = <0x00000009 0x00000014
					0x00000007 0x00000003 0x00000006 0x00000004
					0x00000002 0x00000009 0x00000003 0x00000003
					0x00000002 0x00000002 0x00000002 0x00000005
					0x00000003 0x00000008 0x0000000b 0x0000021f
					0x00000000 0x00000003 0x00000003 0x00000003
					0x00000008 0x00000001 0x0000000a 0x00000015
					0x00000003 0x00000008 0x00000004 0x00000006
					0x00000002 0x00000270 0x00000000 0x00000001
					0x00000000 0x00000000 0x00000282 0xa07c04ae
					0x007e4010 0x00000000 0x00000000 0x0000000e
					0x00000000 0x00000000 0x00000000 0x00000000>;
			};

			emc-table@300000 {
				reg = <300000>;
				compatible = "nvidia,tegra20-emc-table";
				clock-frequency = <300000>;
				nvidia,emc-registers = <0x00000012 0x00000027
					0x0000000d 0x00000006 0x00000007 0x00000005
					0x00000003 0x00000009 0x00000006 0x00000006
					0x00000003 0x00000003 0x00000002 0x00000006
					0x00000003 0x00000009 0x0000000c 0x0000045f
					0x00000000 0x00000004 0x00000004 0x00000006
					0x00000008 0x00000001 0x0000000e 0x0000002a
					0x00000003 0x0000000f 0x00000007 0x00000005
					0x00000002 0x000004e1 0x00000005 0x00000002
					0x00000000 0x00000000 0x00000282 0xe059048b
					0x007e0010 0x00000000 0x00000000 0x0000001b
					0x00000000 0x00000000 0x00000000 0x00000000>;
			};
		};
	};
};
